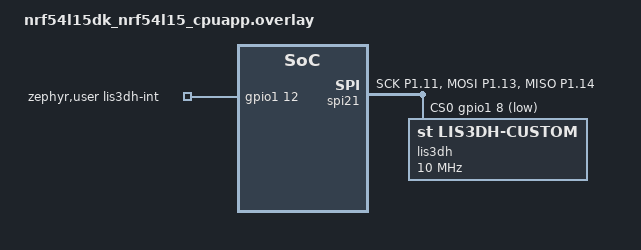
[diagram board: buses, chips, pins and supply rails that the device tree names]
// To get started, press Ctrl+Space to bring up the completion menu and view the available nodes.

// You can also use the buttons in the sidebar to perform actions on nodes.
// Actions currently available include:

// * Enabling / disabling the node
// * Adding the bus to a bus
// * Removing the node
// * Connecting ADC channels

// For more help, browse the DeviceTree documentation at https: //docs.zephyrproject.org/latest/guides/dts/index.html
// You can also visit the nRF DeviceTree extension documentation at https: //docs.nordicsemi.com/bundle/nrf-connect-vscode/page/guides/ncs_configure_app.html#devicetree-support-in-the-extension

/{
	zephyr,user {
		lis3dh-int-gpios = <&gpio1 12 GPIO_ACTIVE_HIGH>;
	};
};
&spi21 {
	status = "okay";
	pinctrl-0 = <&spi21_default>;
	pinctrl-names = "default";
	lis3dh:lis3dh@0 {
		compatible = "st,lis3dh-custom";
		reg = <0x0>;
		spi-max-frequency = <DT_FREQ_M(10)>;
	};

	cs-gpios = <&gpio1 8 GPIO_ACTIVE_LOW>;
};

&pinctrl {
	spi21_default: spi21_default {
		group1 {
			psels = <NRF_PSEL(SPIM_SCK, 1, 11)>,
					<NRF_PSEL(SPIM_MOSI, 1, 13)>,
					<NRF_PSEL(SPIM_MISO, 1, 14)>;
		};
	};
};
